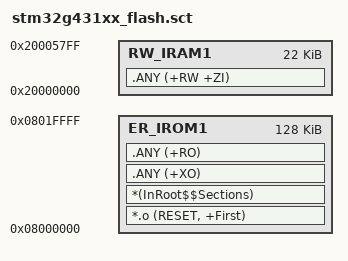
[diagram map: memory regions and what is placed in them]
; STM32G431RBT6: Flash 128KB, SRAM1+SRAM2 = 22KB at 0x20000000
LR_IROM1 0x08000000 0x00020000  {
  ER_IROM1 0x08000000 0x00020000  {
   *.o (RESET, +First)
   *(InRoot$$Sections)
   .ANY (+XO)
   .ANY (+RO)
  }
  RW_IRAM1 0x20000000 0x00005800  {
   .ANY (+RW +ZI)
  }
}
